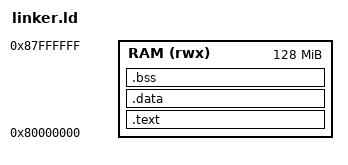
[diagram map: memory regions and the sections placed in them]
OUTPUT_ARCH("riscv")
ENTRY(_start)

MEMORY
{
    RAM (rwx) : ORIGIN = 0x80000000, LENGTH = 128M
}

SECTIONS
{
    .text : {
        *(.text.boot)
        *(.text .text.*)
        *(.rodata .rodata.*)
    } > RAM

    .data : {
        *(.data .data.*)
    } > RAM

    .bss : {
        . = ALIGN(4);
        __bss_start = .;
        *(.bss .bss.*)
        *(COMMON)
        . = ALIGN(4);
        __bss_end = .;
        _stack_bottom = .;
        . += 0x1000;
        _staxk_top = 0;
    } > RAM
}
